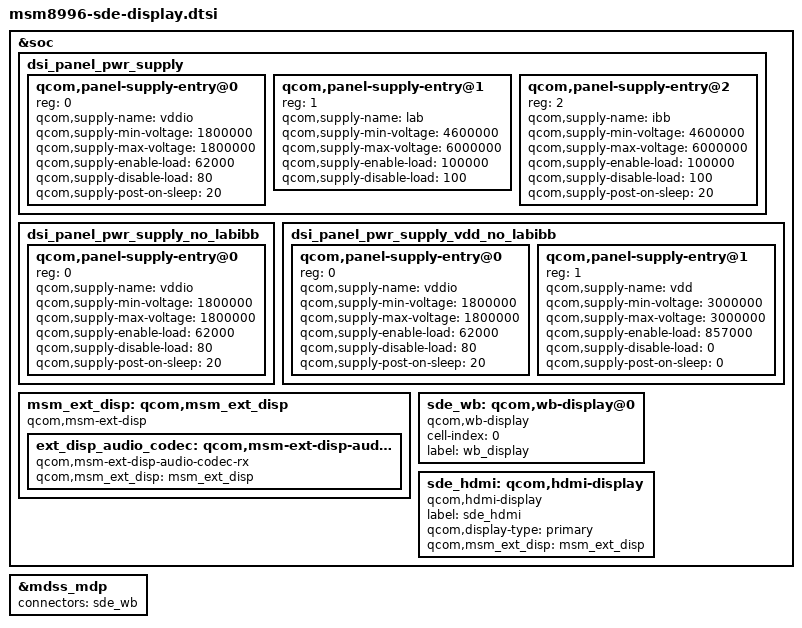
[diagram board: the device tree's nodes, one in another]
/* Copyright (c) 2016-2017, The Linux Foundation. All rights reserved.
 *
 * This program is free software; you can redistribute it and/or modify
 * it under the terms of the GNU General Public License version 2 and
 * only version 2 as published by the Free Software Foundation.
 *
 * This program is distributed in the hope that it will be useful,
 * but WITHOUT ANY WARRANTY; without even the implied warranty of
 * MERCHANTABILITY or FITNESS FOR A PARTICULAR PURPOSE.  See the
 * GNU General Public License for more details.
 */

#include "msm8996-mdss-panels.dtsi"
#include "dsi-panel-sharp-1080p-cmd.dtsi"

&soc {
	dsi_panel_pwr_supply: dsi_panel_pwr_supply {
		#address-cells = <1>;
		#size-cells = <0>;

		qcom,panel-supply-entry@0 {
			reg = <0>;
			qcom,supply-name = "vddio";
			qcom,supply-min-voltage = <1800000>;
			qcom,supply-max-voltage = <1800000>;
			qcom,supply-enable-load = <62000>;
			qcom,supply-disable-load = <80>;
			qcom,supply-post-on-sleep = <20>;
		};

		qcom,panel-supply-entry@1 {
			reg = <1>;
			qcom,supply-name = "lab";
			qcom,supply-min-voltage = <4600000>;
			qcom,supply-max-voltage = <6000000>;
			qcom,supply-enable-load = <100000>;
			qcom,supply-disable-load = <100>;
		};

		qcom,panel-supply-entry@2 {
			reg = <2>;
			qcom,supply-name = "ibb";
			qcom,supply-min-voltage = <4600000>;
			qcom,supply-max-voltage = <6000000>;
			qcom,supply-enable-load = <100000>;
			qcom,supply-disable-load = <100>;
			qcom,supply-post-on-sleep = <20>;
		};
	};

	dsi_panel_pwr_supply_no_labibb: dsi_panel_pwr_supply_no_labibb {
		#address-cells = <1>;
		#size-cells = <0>;

		qcom,panel-supply-entry@0 {
			reg = <0>;
			qcom,supply-name = "vddio";
			qcom,supply-min-voltage = <1800000>;
			qcom,supply-max-voltage = <1800000>;
			qcom,supply-enable-load = <62000>;
			qcom,supply-disable-load = <80>;
			qcom,supply-post-on-sleep = <20>;
		};
	};

	dsi_panel_pwr_supply_vdd_no_labibb: dsi_panel_pwr_supply_vdd_no_labibb {
		#address-cells = <1>;
		#size-cells = <0>;

		qcom,panel-supply-entry@0 {
			reg = <0>;
			qcom,supply-name = "vddio";
			qcom,supply-min-voltage = <1800000>;
			qcom,supply-max-voltage = <1800000>;
			qcom,supply-enable-load = <62000>;
			qcom,supply-disable-load = <80>;
			qcom,supply-post-on-sleep = <20>;
		};

		qcom,panel-supply-entry@1 {
			reg = <1>;
			qcom,supply-name = "vdd";
			qcom,supply-min-voltage = <3000000>;
			qcom,supply-max-voltage = <3000000>;
			qcom,supply-enable-load = <857000>;
			qcom,supply-disable-load = <0>;
			qcom,supply-post-on-sleep = <0>;
		};
	};

	msm_ext_disp: qcom,msm_ext_disp {
		compatible = "qcom,msm-ext-disp";

		ext_disp_audio_codec: qcom,msm-ext-disp-audio-codec-rx {
			compatible = "qcom,msm-ext-disp-audio-codec-rx";
			qcom,msm_ext_disp = <&msm_ext_disp>;
		};
	};

	sde_wb: qcom,wb-display@0 {
		compatible = "qcom,wb-display";
		cell-index = <0>;
		label = "wb_display";
	};

	sde_hdmi: qcom,hdmi-display {
		compatible = "qcom,hdmi-display";
		label = "sde_hdmi";
		qcom,display-type = "primary";
		qcom,msm_ext_disp = <&msm_ext_disp>;
	};
};

&mdss_mdp {
	connectors = <&sde_wb>; // &sde_hdmi_tx &sde_hdmi>;
};

